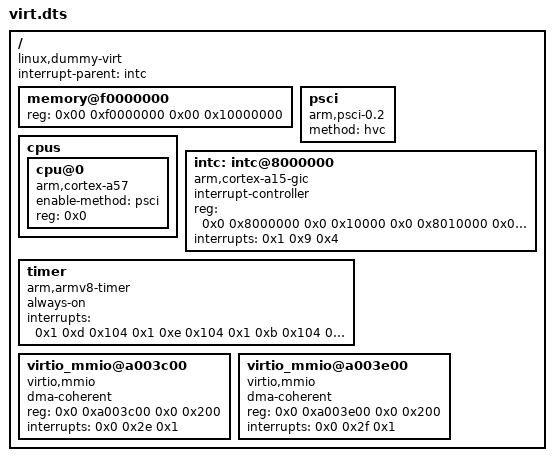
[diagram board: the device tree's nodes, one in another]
/dts-v1/;

/ {
    compatible = "linux,dummy-virt";
    #address-cells = <2>;
    #size-cells = <2>;
    interrupt-parent = <&intc>;

    memory@f0000000 {
        device_type = "memory";
        reg = <0x00 0xf0000000 0x00 0x10000000>;
    };

    psci {
        compatible = "arm,psci-0.2";
        method = "hvc";
    };

    cpus {
        #address-cells = <1>;
        #size-cells = <0>;
        cpu@0 {
            compatible = "arm,cortex-a57";
            device_type = "cpu";
            enable-method = "psci";
            reg = <0x0>;
        };
    };

    intc: intc@8000000 {
        compatible = "arm,cortex-a15-gic";
        interrupt-controller;
        ranges;
        #address-cells = <2>;
        #size-cells = <2>;
        #interrupt-cells = <3>;
        reg = < 0x0 0x8000000 0x0 0x10000 0x0 0x8010000 0x0 0x10000
                0x0 0x8030000 0x0 0x10000 0x0 0x8040000 0x0 0x10000 >;
        interrupts = <0x1 0x9 0x4>;
    };

    timer {
        compatible = "arm,armv8-timer", "arm,armv7-timer";
        always-on;
        interrupts = <0x1 0xd 0x104 0x1 0xe 0x104 0x1 0xb 0x104 0x1 0xa 0x104>;
    };

    /* 9p, irq 78 */
    virtio_mmio@a003c00 {
        compatible = "virtio,mmio";
        dma-coherent;
        reg = <0x0 0xa003c00 0x0 0x200>;
        interrupts = <0x0 0x2e 0x1>;
    };

    /* net, irq 79 */
    virtio_mmio@a003e00 {
        compatible = "virtio,mmio";
        dma-coherent;
        reg = <0x0 0xa003e00 0x0 0x200>;
        interrupts = <0x0 0x2f 0x1>;
    };

};
